# ionuc505 register map
Registers are 32-bit, access not given, no defined reset value unless marked. A register's access mark holds for its fields unless they carry their own. Addresses are absolute; registers are grouped by the start of their names; [hi:lo] are bit positions.

## UART0
0x400EC000 UART0_UART_DAT
  [7:0] DAT
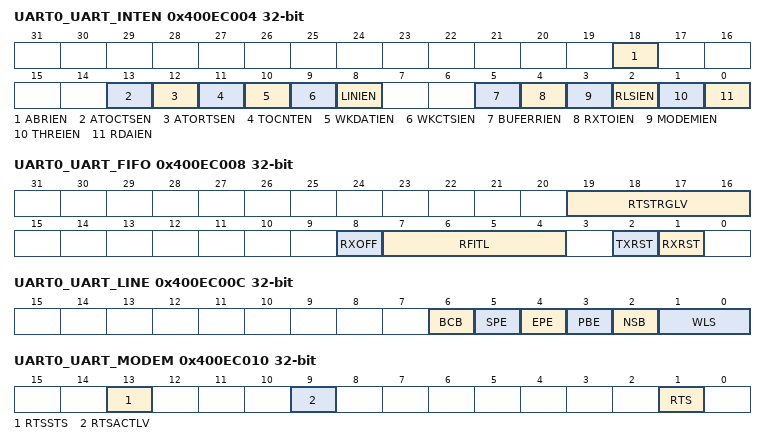
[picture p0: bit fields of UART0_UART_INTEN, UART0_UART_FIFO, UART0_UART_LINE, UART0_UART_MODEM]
0x400EC004 UART0_UART_INTEN
  [18] ABRIEN, [13] ATOCTSEN, [12] ATORTSEN, [11] TOCNTEN, [10] WKDATIEN, [9] WKCTSIEN, [8] LINIEN, [5] BUFERRIEN, [4] RXTOIEN, [3] MODEMIEN, [2] RLSIEN, [1] THREIEN, [0] RDAIEN
0x400EC008 UART0_UART_FIFO
  [19:16] RTSTRGLV, [8] RXOFF, [7:4] RFITL, [2] TXRST, [1] RXRST
0x400EC00C UART0_UART_LINE
  [6] BCB, [5] SPE, [4] EPE, [3] PBE, [2] NSB, [1:0] WLS
0x400EC010 UART0_UART_MODEM
  [13] RTSSTS, [9] RTSACTLV, [1] RTS
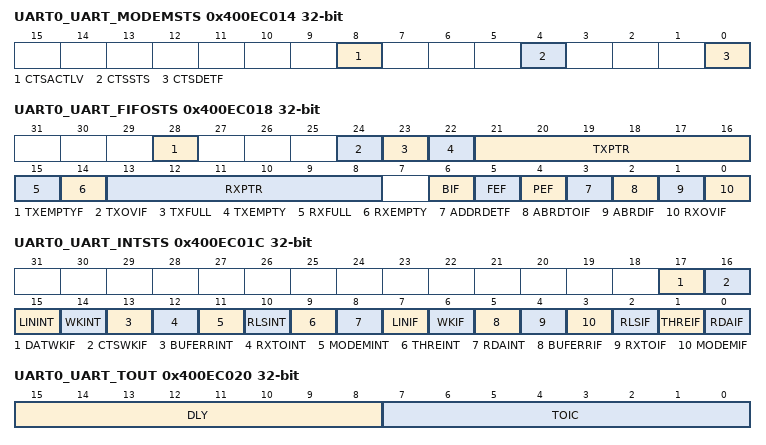
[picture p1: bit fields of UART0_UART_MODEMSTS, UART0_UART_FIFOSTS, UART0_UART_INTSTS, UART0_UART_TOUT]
0x400EC014 UART0_UART_MODEMSTS
  [8] CTSACTLV, [4] CTSSTS, [0] CTSDETF
0x400EC018 UART0_UART_FIFOSTS
  [28] TXEMPTYF, [24] TXOVIF, [23] TXFULL, [22] TXEMPTY, [21:16] TXPTR, [15] RXFULL, [14] RXEMPTY, [13:8] RXPTR, [6] BIF, [5] FEF, [4] PEF, [3] ADDRDETF, [2] ABRDTOIF, [1] ABRDIF, [0] RXOVIF
0x400EC01C UART0_UART_INTSTS
  [17] DATWKIF, [16] CTSWKIF, [15] LININT, [14] WKINT, [13] BUFERRINT, [12] RXTOINT, [11] MODEMINT, [10] RLSINT, [9] THREINT, [8] RDAINT, [7] LINIF, [6] WKIF, [5] BUFERRIF, [4] RXTOIF, [3] MODEMIF, [2] RLSIF, [1] THREIF, [0] RDAIF
0x400EC020 UART0_UART_TOUT
  [15:8] DLY, [7:0] TOIC
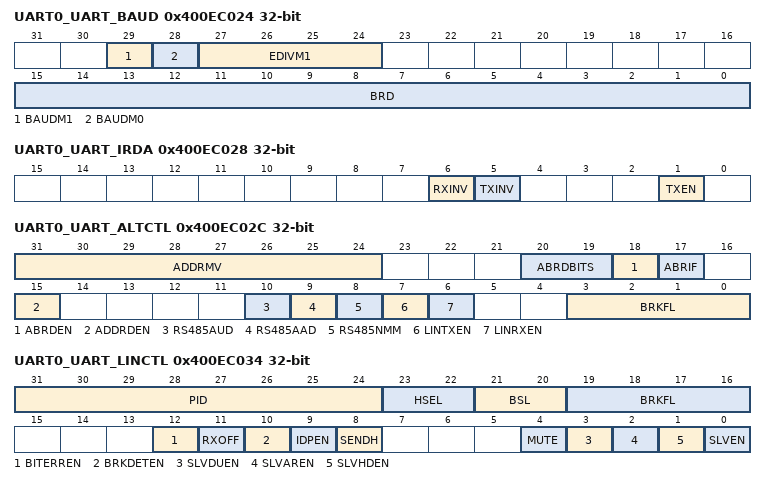
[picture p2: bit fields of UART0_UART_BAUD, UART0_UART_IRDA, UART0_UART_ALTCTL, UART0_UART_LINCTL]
0x400EC024 UART0_UART_BAUD
  [29] BAUDM1, [28] BAUDM0, [27:24] EDIVM1, [15:0] BRD
0x400EC028 UART0_UART_IRDA
  [6] RXINV, [5] TXINV, [1] TXEN
0x400EC02C UART0_UART_ALTCTL
  [31:24] ADDRMV, [20:19] ABRDBITS, [18] ABRDEN, [17] ABRIF, [15] ADDRDEN, [10] RS485AUD, [9] RS485AAD, [8] RS485NMM, [7] LINTXEN, [6] LINRXEN, [3:0] BRKFL
0x400EC030 UART0_UART_FUNCSEL
  [1:0] FUNCSEL
0x400EC034 UART0_UART_LINCTL
  [31:24] PID, [23:22] HSEL, [21:20] BSL, [19:16] BRKFL, [12] BITERREN, [11] RXOFF, [10] BRKDETEN, [9] IDPEN, [8] SENDH, [4] MUTE, [3] SLVDUEN, [2] SLVAREN, [1] SLVHDEN, [0] SLVEN
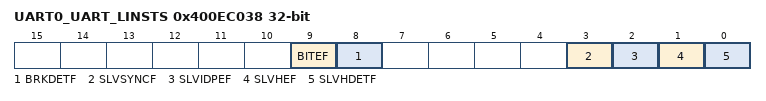
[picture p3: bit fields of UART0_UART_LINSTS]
0x400EC038 UART0_UART_LINSTS
  [9] BITEF, [8] BRKDETF, [3] SLVSYNCF, [2] SLVIDPEF, [1] SLVHEF, [0] SLVHDETF

## UART1
0x400ED000 UART1_UART_DAT
  [7:0] DAT
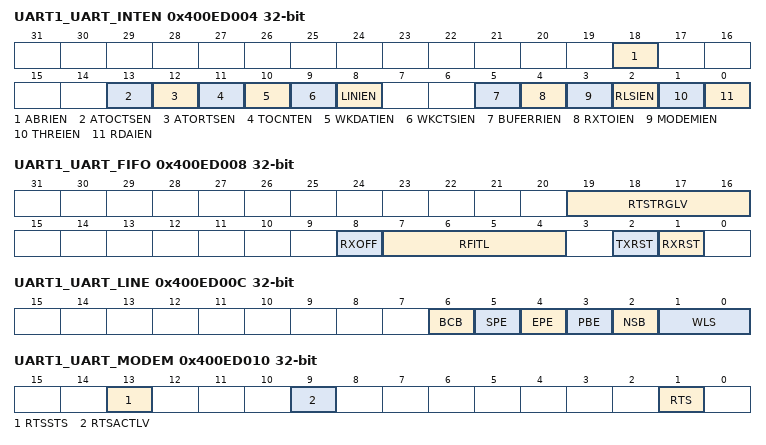
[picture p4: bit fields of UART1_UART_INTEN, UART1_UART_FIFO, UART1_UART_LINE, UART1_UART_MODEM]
0x400ED004 UART1_UART_INTEN
  [18] ABRIEN, [13] ATOCTSEN, [12] ATORTSEN, [11] TOCNTEN, [10] WKDATIEN, [9] WKCTSIEN, [8] LINIEN, [5] BUFERRIEN, [4] RXTOIEN, [3] MODEMIEN, [2] RLSIEN, [1] THREIEN, [0] RDAIEN
0x400ED008 UART1_UART_FIFO
  [19:16] RTSTRGLV, [8] RXOFF, [7:4] RFITL, [2] TXRST, [1] RXRST
0x400ED00C UART1_UART_LINE
  [6] BCB, [5] SPE, [4] EPE, [3] PBE, [2] NSB, [1:0] WLS
0x400ED010 UART1_UART_MODEM
  [13] RTSSTS, [9] RTSACTLV, [1] RTS
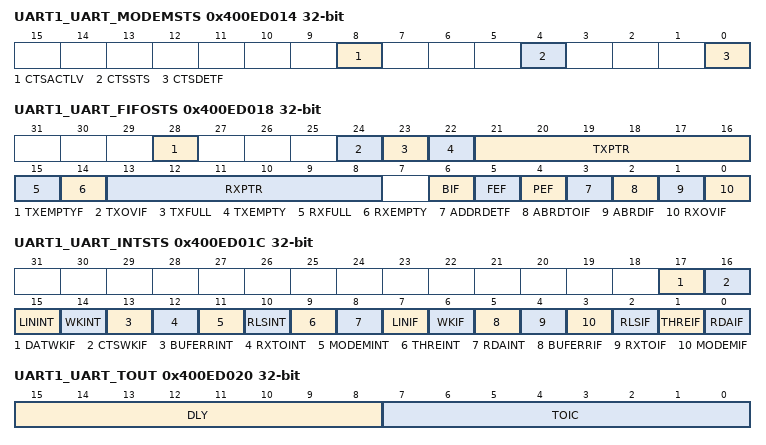
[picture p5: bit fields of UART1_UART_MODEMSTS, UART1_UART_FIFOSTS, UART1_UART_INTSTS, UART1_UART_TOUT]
0x400ED014 UART1_UART_MODEMSTS
  [8] CTSACTLV, [4] CTSSTS, [0] CTSDETF
0x400ED018 UART1_UART_FIFOSTS
  [28] TXEMPTYF, [24] TXOVIF, [23] TXFULL, [22] TXEMPTY, [21:16] TXPTR, [15] RXFULL, [14] RXEMPTY, [13:8] RXPTR, [6] BIF, [5] FEF, [4] PEF, [3] ADDRDETF, [2] ABRDTOIF, [1] ABRDIF, [0] RXOVIF
0x400ED01C UART1_UART_INTSTS
  [17] DATWKIF, [16] CTSWKIF, [15] LININT, [14] WKINT, [13] BUFERRINT, [12] RXTOINT, [11] MODEMINT, [10] RLSINT, [9] THREINT, [8] RDAINT, [7] LINIF, [6] WKIF, [5] BUFERRIF, [4] RXTOIF, [3] MODEMIF, [2] RLSIF, [1] THREIF, [0] RDAIF
0x400ED020 UART1_UART_TOUT
  [15:8] DLY, [7:0] TOIC
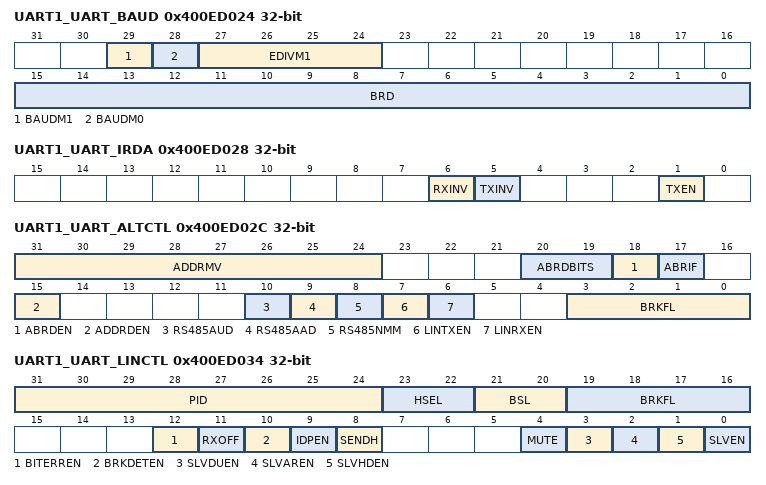
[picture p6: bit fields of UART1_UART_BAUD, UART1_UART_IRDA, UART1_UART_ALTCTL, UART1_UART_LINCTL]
0x400ED024 UART1_UART_BAUD
  [29] BAUDM1, [28] BAUDM0, [27:24] EDIVM1, [15:0] BRD
0x400ED028 UART1_UART_IRDA
  [6] RXINV, [5] TXINV, [1] TXEN
0x400ED02C UART1_UART_ALTCTL
  [31:24] ADDRMV, [20:19] ABRDBITS, [18] ABRDEN, [17] ABRIF, [15] ADDRDEN, [10] RS485AUD, [9] RS485AAD, [8] RS485NMM, [7] LINTXEN, [6] LINRXEN, [3:0] BRKFL
0x400ED030 UART1_UART_FUNCSEL
  [1:0] FUNCSEL
0x400ED034 UART1_UART_LINCTL
  [31:24] PID, [23:22] HSEL, [21:20] BSL, [19:16] BRKFL, [12] BITERREN, [11] RXOFF, [10] BRKDETEN, [9] IDPEN, [8] SENDH, [4] MUTE, [3] SLVDUEN, [2] SLVAREN, [1] SLVHDEN, [0] SLVEN
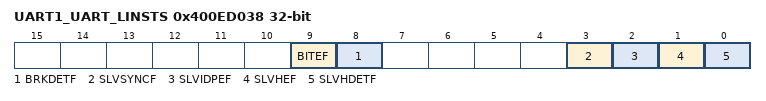
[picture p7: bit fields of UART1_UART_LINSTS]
0x400ED038 UART1_UART_LINSTS
  [9] BITEF, [8] BRKDETF, [3] SLVSYNCF, [2] SLVIDPEF, [1] SLVHEF, [0] SLVHDETF

## UART2
0x400EE000 UART2_UART_DAT
  [7:0] DAT
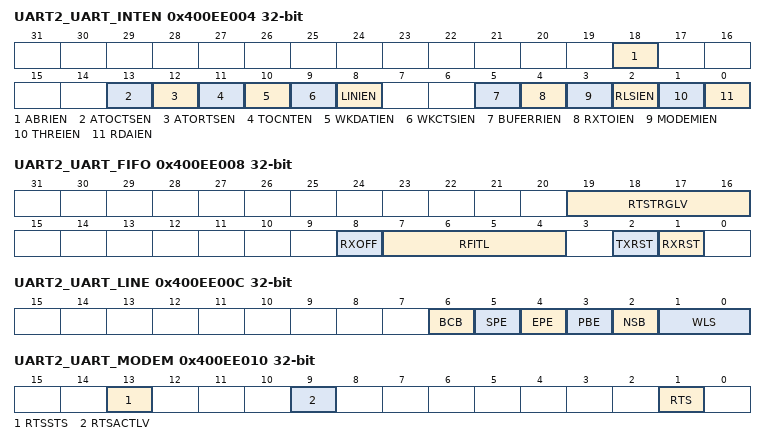
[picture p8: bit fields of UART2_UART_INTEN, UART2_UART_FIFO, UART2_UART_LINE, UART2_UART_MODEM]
0x400EE004 UART2_UART_INTEN
  [18] ABRIEN, [13] ATOCTSEN, [12] ATORTSEN, [11] TOCNTEN, [10] WKDATIEN, [9] WKCTSIEN, [8] LINIEN, [5] BUFERRIEN, [4] RXTOIEN, [3] MODEMIEN, [2] RLSIEN, [1] THREIEN, [0] RDAIEN
0x400EE008 UART2_UART_FIFO
  [19:16] RTSTRGLV, [8] RXOFF, [7:4] RFITL, [2] TXRST, [1] RXRST
0x400EE00C UART2_UART_LINE
  [6] BCB, [5] SPE, [4] EPE, [3] PBE, [2] NSB, [1:0] WLS
0x400EE010 UART2_UART_MODEM
  [13] RTSSTS, [9] RTSACTLV, [1] RTS
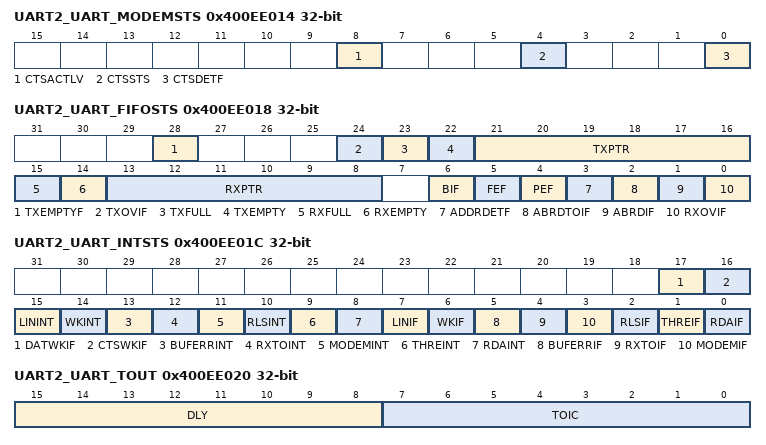
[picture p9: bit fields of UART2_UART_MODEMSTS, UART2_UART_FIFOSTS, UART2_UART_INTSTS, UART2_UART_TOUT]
0x400EE014 UART2_UART_MODEMSTS
  [8] CTSACTLV, [4] CTSSTS, [0] CTSDETF
0x400EE018 UART2_UART_FIFOSTS
  [28] TXEMPTYF, [24] TXOVIF, [23] TXFULL, [22] TXEMPTY, [21:16] TXPTR, [15] RXFULL, [14] RXEMPTY, [13:8] RXPTR, [6] BIF, [5] FEF, [4] PEF, [3] ADDRDETF, [2] ABRDTOIF, [1] ABRDIF, [0] RXOVIF
0x400EE01C UART2_UART_INTSTS
  [17] DATWKIF, [16] CTSWKIF, [15] LININT, [14] WKINT, [13] BUFERRINT, [12] RXTOINT, [11] MODEMINT, [10] RLSINT, [9] THREINT, [8] RDAINT, [7] LINIF, [6] WKIF, [5] BUFERRIF, [4] RXTOIF, [3] MODEMIF, [2] RLSIF, [1] THREIF, [0] RDAIF
0x400EE020 UART2_UART_TOUT
  [15:8] DLY, [7:0] TOIC
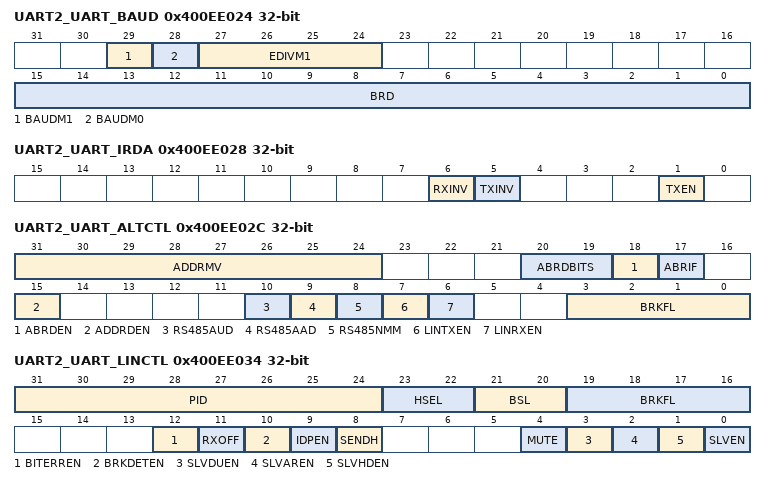
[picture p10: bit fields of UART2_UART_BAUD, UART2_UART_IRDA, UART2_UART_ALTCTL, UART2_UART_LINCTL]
0x400EE024 UART2_UART_BAUD
  [29] BAUDM1, [28] BAUDM0, [27:24] EDIVM1, [15:0] BRD
0x400EE028 UART2_UART_IRDA
  [6] RXINV, [5] TXINV, [1] TXEN
0x400EE02C UART2_UART_ALTCTL
  [31:24] ADDRMV, [20:19] ABRDBITS, [18] ABRDEN, [17] ABRIF, [15] ADDRDEN, [10] RS485AUD, [9] RS485AAD, [8] RS485NMM, [7] LINTXEN, [6] LINRXEN, [3:0] BRKFL
0x400EE030 UART2_UART_FUNCSEL
  [1:0] FUNCSEL
0x400EE034 UART2_UART_LINCTL
  [31:24] PID, [23:22] HSEL, [21:20] BSL, [19:16] BRKFL, [12] BITERREN, [11] RXOFF, [10] BRKDETEN, [9] IDPEN, [8] SENDH, [4] MUTE, [3] SLVDUEN, [2] SLVAREN, [1] SLVHDEN, [0] SLVEN
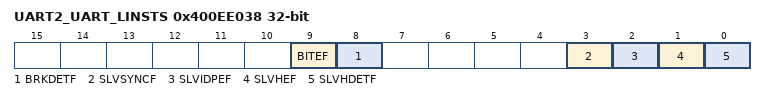
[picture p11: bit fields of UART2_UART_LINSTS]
0x400EE038 UART2_UART_LINSTS
  [9] BITEF, [8] BRKDETF, [3] SLVSYNCF, [2] SLVIDPEF, [1] SLVHEF, [0] SLVHDETF
